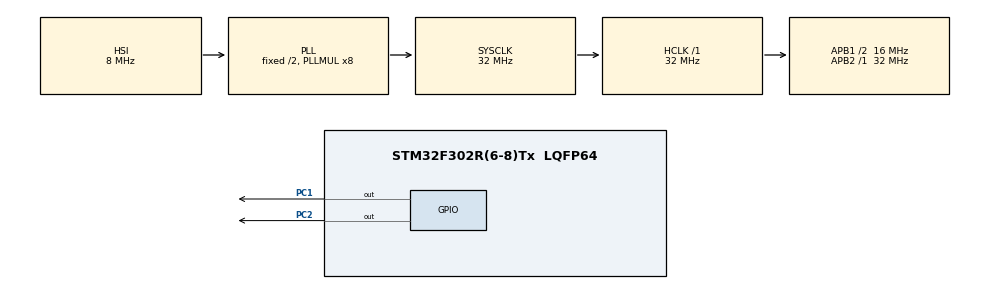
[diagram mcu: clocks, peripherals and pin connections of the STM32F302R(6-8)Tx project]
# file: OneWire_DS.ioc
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Mcu.Family=STM32F3
Mcu.Name=STM32F302R(6-8)Tx
Mcu.Package=LQFP64
NVIC.PriorityGroup=NVIC_PRIORITYGROUP_4
PC1.GPIO_ModeDefaultOutputPP=GPIO_MODE_OUTPUT_OD
PC1.GPIO_PuPd=GPIO_PULLUP
PC1.Signal=GPIO_Output
PC2.PinState=GPIO_PIN_SET
PC2.Signal=GPIO_Output
PF0-OSC_IN.Mode=HSE-External-Oscillator
PF0-OSC_IN.Signal=RCC_OSC_IN
PF1-OSC_OUT.Mode=HSE-External-Oscillator
PF1-OSC_OUT.Signal=RCC_OSC_OUT
ProjectManager.HeapSize=0x200
ProjectManager.StackSize=0x400
ProjectManager.TargetToolchain=MDK-ARM V5.27
RCC.AHBFreq_Value=32000000
RCC.APB1CLKDivider=RCC_HCLK_DIV2
RCC.APB1Freq_Value=16000000
RCC.APB1TimFreq_Value=32000000
RCC.APB2Freq_Value=32000000
RCC.APB2TimFreq_Value=32000000
RCC.CortexFreq_Value=32000000
RCC.HCLKFreq_Value=32000000
RCC.HSE_VALUE=8000000
RCC.HSI_VALUE=8000000
RCC.LSE_VALUE=32768
RCC.PLLMUL=RCC_PLL_MUL8
RCC.SYSCLKFreq_VALUE=32000000
RCC.SYSCLKSourceVirtual=RCC_SYSCLKSOURCE_PLLCLK
RCC.USBFreq_Value=32000000
TIM6.Period=0xffff-1
TIM6.Prescaler=32-1
VP_TIM6_VS_ClockSourceINT.Mode=Enable_Timer
board=custom

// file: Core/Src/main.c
/* USER CODE BEGIN Header */
/**
  ******************************************************************************
  * @file           : main.c
  * @brief          : Main program body
  ******************************************************************************
  * @attention
  *
  * <h2><center>&copy; Copyright (c) 2021 STMicroelectronics.
  * All rights reserved.</center></h2>
  *
  * This software component is licensed by ST under BSD 3-Clause license,
  * the "License"; You may not use this file except in compliance with the
  * License. You may obtain a copy of the License at:
  *                        opensource.org/licenses/BSD-3-Clause
  *
  ******************************************************************************
  */
/* USER CODE END Header */
#include "main.h"

/* USER CODE BEGIN Includes */
#include "OneWire_Hi4Tech.h"
/* USER CODE END Includes */

/* USER CODE BEGIN PTD */
#define DS28E18_PORT GPIOC
#define DS28E18_PIN GPIO_PIN_2
#define PullUp_Pin GPIO_PIN_1

/* USER CODE END PTD */

TIM_HandleTypeDef htim6;

void SystemClock_Config(void);
static void MX_GPIO_Init(void);
static void MX_TIM6_Init(void);

int main(void)
{

  /* MCU Configuration--------------------------------------------------------*/

  /* Reset of all peripherals, Initializes the Flash interface and the Systick. */
  HAL_Init();

  /* Configure the system clock */
  SystemClock_Config();

  /* Initialize all configured peripherals */
  MX_GPIO_Init();
  MX_TIM6_Init();
  /* USER CODE BEGIN 2 */
	HAL_TIM_Base_Start(&htim6);
	init_OW();
  /* USER CODE END 2 */

  /* Infinite loop */
  while (1)
  {

    /* USER CODE BEGIN 3 */

			run_OW();

	}
  /* USER CODE END 3 */
}

void SystemClock_Config(void)
{
  RCC_OscInitTypeDef RCC_OscInitStruct = {0};
  RCC_ClkInitTypeDef RCC_ClkInitStruct = {0};

  /** Initializes the RCC Oscillators according to the specified parameters
  * in the RCC_OscInitTypeDef structure.
  */
  RCC_OscInitStruct.OscillatorType = RCC_OSCILLATORTYPE_HSI;
  RCC_OscInitStruct.HSIState = RCC_HSI_ON;
  RCC_OscInitStruct.HSICalibrationValue = RCC_HSICALIBRATION_DEFAULT;
  RCC_OscInitStruct.PLL.PLLState = RCC_PLL_ON;
  RCC_OscInitStruct.PLL.PLLSource = RCC_PLLSOURCE_HSI;
  RCC_OscInitStruct.PLL.PLLMUL = RCC_PLL_MUL8;
  if (HAL_RCC_OscConfig(&RCC_OscInitStruct) != HAL_OK)
  {
    Error_Handler();
  }
  /** Initializes the CPU, AHB and APB buses clocks
  */
  RCC_ClkInitStruct.ClockType = RCC_CLOCKTYPE_HCLK|RCC_CLOCKTYPE_SYSCLK
                              |RCC_CLOCKTYPE_PCLK1|RCC_CLOCKTYPE_PCLK2;
  RCC_ClkInitStruct.SYSCLKSource = RCC_SYSCLKSOURCE_PLLCLK;
  RCC_ClkInitStruct.AHBCLKDivider = RCC_SYSCLK_DIV1;
  RCC_ClkInitStruct.APB1CLKDivider = RCC_HCLK_DIV2;
  RCC_ClkInitStruct.APB2CLKDivider = RCC_HCLK_DIV1;

  if (HAL_RCC_ClockConfig(&RCC_ClkInitStruct, FLASH_LATENCY_1) != HAL_OK)
  {
    Error_Handler();
  }
}

static void MX_TIM6_Init(void)
{

  TIM_MasterConfigTypeDef sMasterConfig = {0};

  htim6.Instance = TIM6;
  htim6.Init.Prescaler = 32-1;
  htim6.Init.CounterMode = TIM_COUNTERMODE_UP;
  htim6.Init.Period = 0xffff-1;
  htim6.Init.AutoReloadPreload = TIM_AUTORELOAD_PRELOAD_DISABLE;
  if (HAL_TIM_Base_Init(&htim6) != HAL_OK)
  {
    Error_Handler();
  }
  sMasterConfig.MasterOutputTrigger = TIM_TRGO_RESET;
  sMasterConfig.MasterSlaveMode = TIM_MASTERSLAVEMODE_DISABLE;
  if (HAL_TIMEx_MasterConfigSynchronization(&htim6, &sMasterConfig) != HAL_OK)
  {
    Error_Handler();
  }

}

static void MX_GPIO_Init(void)
{
  GPIO_InitTypeDef GPIO_InitStruct = {0};

  /* GPIO Ports Clock Enable */
  __HAL_RCC_GPIOF_CLK_ENABLE();
  __HAL_RCC_GPIOC_CLK_ENABLE();

  /*Configure GPIO pin Output Level */
  HAL_GPIO_WritePin(GPIOC, GPIO_PIN_1, GPIO_PIN_SET);

  /*Configure GPIO pin Output Level */
  HAL_GPIO_WritePin(GPIOC, GPIO_PIN_2, GPIO_PIN_SET);

  /*Configure GPIO pin : PC1 */
  GPIO_InitStruct.Pin = GPIO_PIN_1;
  GPIO_InitStruct.Mode = GPIO_MODE_OUTPUT_OD;
  GPIO_InitStruct.Pull = GPIO_PULLUP;
  GPIO_InitStruct.Speed = GPIO_SPEED_FREQ_LOW;
  HAL_GPIO_Init(GPIOC, &GPIO_InitStruct);

  /*Configure GPIO pin : PC2 */
  GPIO_InitStruct.Pin = GPIO_PIN_2;
  GPIO_InitStruct.Mode = GPIO_MODE_OUTPUT_PP;
  GPIO_InitStruct.Pull = GPIO_NOPULL;
  GPIO_InitStruct.Speed = GPIO_SPEED_FREQ_LOW;
  HAL_GPIO_Init(GPIOC, &GPIO_InitStruct);

}

void Error_Handler(void)
{
}

/************************ (C) COPYRIGHT STMicroelectronics *****END OF FILE****/
